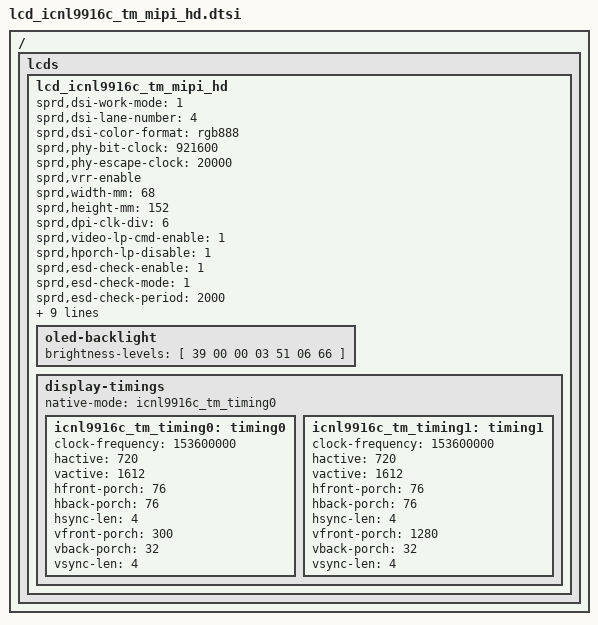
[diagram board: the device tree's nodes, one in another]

/*
 * icnl9916c LCD config dtsi file for spreadtrum
 *
 * Copyright (C) 2022, Spreadtrum Communications Inc.
 *
 * SPDX-License-Identifier: (GPL-2.0+ OR MIT)
 */

/ {
	fragment {
		target-path = "/";
		__overlay__ {
			lcds {
				lcd_icnl9916c_tm_mipi_hd: lcd_icnl9916c_tm_mipi_hd {

					sprd,dsi-work-mode = <1>; /* video burst mode*/
					sprd,dsi-lane-number = <4>;
					sprd,dsi-color-format = "rgb888";

					sprd,phy-bit-clock = <921600>;	/* kbps */
					sprd,phy-escape-clock = <20000>;/* kHz */
					sprd,vrr-enable;  /*90hz 60hz*/
					// sprd,power-gpio-delay = <20>; ms
					sprd,width-mm = <68>;
					sprd,height-mm = <152>;
					sprd,dpi-clk-div = <6>;
					sprd,video-lp-cmd-enable = <1>;
					sprd,hporch-lp-disable = <1>;

					sprd,esd-check-enable = <1>;
					sprd,esd-check-mode = <1>;
					sprd,esd-check-period = <2000>;
					sprd,esd-check-regs = <0xA>;
					sprd,esd-return-code = <0x9c>;

					sprd,reset-on-sequence = <1 5>, <0 5>, <1 10>;
					//sprd,reset-off-sequence = <0 5>;

					sprd,initial-command = [
						39 00 00 04 F0 99 16 0C
						39 00 00 05 BD A1 0A 52 A6
						39 00 00 15 C1 10 20 20 2C 04 4C 4C 04 4C 06 22 40 35 30 07 11 84 4C 00 93
						39 00 00 03 C2 11 05
						39 00 00 05 C8 44 00 0C 96
						39 00 00 03 51 00 00
						15 00 00 02 53 2C
						15 02 00 02 55 01
						39 00 00 18 E0 0C 00 B0 0C 00 0A 8C 29 04 81 1F 00 00 00 00 24 12 08 11 48 47 00 00
						39 00 00 20 E1 0F 1F 2F 3F 4F 5F 6F 7F 90 A0 B0 C0 D0 E0 E8 EC ED EF F1 F3 F5 F7 F9 FB FF FC FD FE FF FF FF
						39 00 00 21 E2 36 24 37 4B 38 72 39 99 3A 1C 3A 9F 3B 22 3B A5 3C 28 3F 50 3D B1 3E 76 3F 3A 3F FF 3F FF 3F FF
						39 00 00 03 35 00 00
						39 78 00 03 11 00 00
						39 14 00 03 29 00 00
						39 00 00 03 6D 02 00
						39 00 00 05 BD A1 0A 52 AE
						39 00 00 04 F0 00 00 00
						];

					sprd,sleep-in-command = [
						39 00 00 02 6D 25
						39 0A 00 01 28
						39 78 00 01 10
						];

					sprd,sleep-out-command = [
						39 78 00 01 11
						39 14 00 01 29
						];

					oled-backlight {
						//default-brightness = <900>;
						//sprd,max-level = <4095>;
						brightness-levels = [
						39 00 00 03 51 06 66
						];
					};

					display-timings {
						native-mode = <&icnl9916c_tm_timing0>;

						icnl9916c_tm_timing0: timing0 {
							clock-frequency = <153600000>;
							hactive = <720>;
							vactive = <1612>;
							hfront-porch = <76>;
							hback-porch = <76>;
							hsync-len = <4>;
							vfront-porch = <300>;
							vback-porch = <32>;
							vsync-len = <4>;
						};
						icnl9916c_tm_timing1: timing1 {
							clock-frequency = <153600000>;
							hactive = <720>;
							vactive = <1612>;
							hfront-porch = <76>;
							hback-porch = <76>;
							hsync-len = <4>;
							vfront-porch = <1280>;
							vback-porch = <32>;
							vsync-len = <4>;
						};
					};
				};
			};
		};
	};
};
